# APM32F446 register map
File version: 1.0
CPU: CM4 r0p1, little endian, MPU, FPU, 4 interrupt priority bits
Registers are 32-bit, read-write, reset 0x0 unless marked. A register's access mark holds for its fields unless they carry their own. Offsets are from the block's base; [hi:lo] are bit positions; {n}, {i} and the like mark numbered series; 'fields as' and 'values as' point back to an identical list.

## CAN0 — Configurable Controller local area network
Base 0x40024000
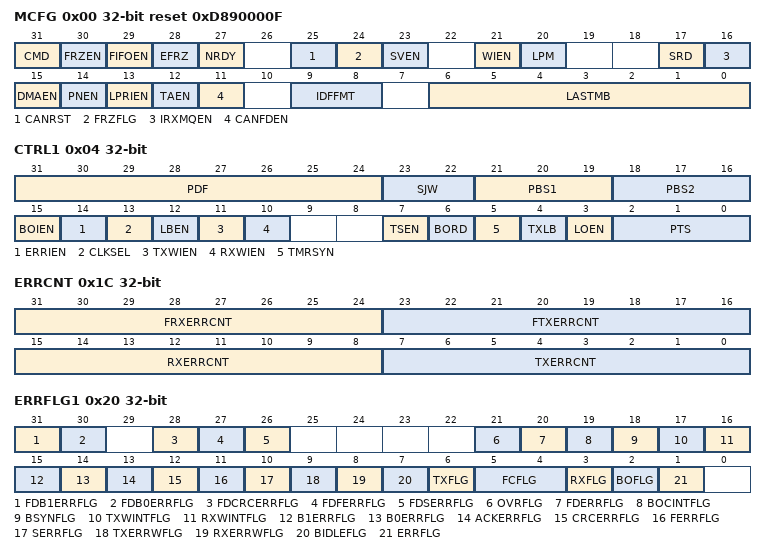
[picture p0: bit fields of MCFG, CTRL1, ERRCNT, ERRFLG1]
0x00 MCFG reset 0xD890000F — Module Configure register
  [31] CMD — CAN Module Disable
    0=Enable the CAN module; 1=Disable the CAN module
  [30] FRZEN — Freeze Mode Enable
    0=Not enabled to enter Freeze mode; 1=Enabled to enter Freeze mode
  [29] FIFOEN — Rx FIFO Enable
    0=Rx FIFO not enabled; 1=Rx FIFO enabled
  [28] EFRZ — Enter Freeze Mode
    0=No Freeze mode request; 1=Enters Freeze mode if the FRZ bit is asserted
  [27] NRDY ro — Not Ready
    0=CAN module is either in Normal mode, Listen-Only mode or Loop-Back mode
  [25] CANRST — CAN Reset
    0=No reset request; 1=Resets the registers affected by soft reset
  [24] FRZFLG ro — Freeze Mode Flag
    0=CAN not in Freeze mode, prescaler running; 1=CAN in Freeze mode, prescaler stopped
  [23] SVEN — Supervisor Mode Enable
  [21] WIEN — Warning Interrupt Enable
    0=TWRNINT and RWRNINT bits are zero, independent of the values in the error counters; 1=TWRNINT and RWRNINT bits are set when the respective error counter transitions from less than 96 to greater than or equal to 96
  [20] LPM ro — Low-Power Mode
    0=CAN is not in a low-power mode; 1=CAN is in a low-power mode
  [17] SRD — Self Reception Disable
    0=Self reception enabled; 1=Self reception disabled
  [16] IRXMQEN — Individual Receive Masking and Queue Enable
    0=Individual Rx masking and queue feature are disabled. For backward compatibility with legacy applications, the reading of C/S word locks the MB even if it is EMPTY.; 1=Individual Rx masking and queue feature are enabled
  [15] DMAEN — DMA Enable for Rx FIFO
    0=DMA feature for RX FIFO disabled; 1=DMA feature for RX FIFO enabled
  [14] PNEN — Pretended Networking Enable
    0=Pretended Networking mode is disabled; 1=Pretended Networking mode is enabled
  [13] LPRIEN — Local Priority Enable
    0=Local Priority disabled; 1=Local Priority enabled
  [12] TAEN — Tx Abort Mechanism Enable
    0=Abort disabled; 1=Abort enabled
  [11] CANFDEN — CAN FD Operation Enable
    1=CAN FD is enabled. CAN is able to receive and transmit messages in both CAN FD and CAN 2.0 formats.; 0=CAN FD is disabled. CAN is able to receive and transmit messages in CAN 2.0 format.
  [9:8] IDFFMT — Rx FIFO ID Filter Format
    0=Format A: One full ID (standard and extended) per ID Filter Table element; 1=Format B: Two full standard IDs or two partial 14-bit (standard and extended) IDs per ID Filter Table element; 2=Format C: Four partial 8-bit Standard IDs per ID Filter Table element; 3=Format D: All frames rejected
  [6:0] LASTMB — Number of the Last Message Buffer
0x04 CTRL1 — Control register 1
  [31:24] PDF — Prescaler Division Factor
  [23:22] SJW — Resynchronized Jump Width
  [21:19] PBS1 — Phase Buffer Segment 1
  [18:16] PBS2 — Phase Buffer Segment 2
  [15] BOIEN — Bus Off Interrupt Enable
    0=Bus Off interrupt disabled; 1=Bus Off interrupt enabled
  [14] ERRIEN — Error Interrupt Enable
    0=Error interrupt disabled; 1=Error interrupt enabled
  [13] CLKSEL — CAN Engine Clock Source Select
    0=The CAN engine clock source is the oscillator clock. Under this condition, the oscillator clock frequency must be lower than the bus clock.; 1=The CAN engine clock source is the peripheral clock
  [12] LBEN — Loop Back Mode Enable
    0=Loop Back disabled; 1=Loop Back enabled
  [11] TXWIEN — Tx Warning Interrupt Enable
    0=Tx Warning Interrupt disabled; 1=Tx Warning Interrupt enabled
  [10] RXWIEN — Rx Warning Interrupt Enable
    0=Rx Warning Interrupt disabled; 1=Rx Warning Interrupt enabled
  [7] TSEN — Triple Sampling Enable
    0=Just one sample is used to determine the bit value; 1=Three samples are used to determine the value of the received bit: the regular one (sample point) and 2 preceding samples; a majority rule is used
  [6] BORD — Bus Off Recovery Disable
    0=Automatic recovering from Bus Off state enabled; 1=Automatic recovering from Bus Off state disabled
  [5] TMRSYN — Timer Sync Feature Enable
    0=Timer Sync feature disabled; 1=Timer Sync feature enabled
  [4] TXLB — Transmit Lowest Buffer First
    0=Buffer with highest priority is transmitted first; 1=Lowest number buffer is transmitted first
  [3] LOEN — Listen-Only Mode Enable
    0=Listen-Only mode is deactivated; 1=CAN module operates in Listen-Only mode
  [2:0] PTS — Propagation Time Segment
0x08 FRTMR — Free Running Timer register
  [15:0] FRTMR — Free Runnning Timer Value
0x10 RXMASK reset not defined — Rx Mailboxes Global Mask register
  [31:0] RXMASK — Rx Mailboxes Global Mask
0x14 RX14MASK reset not defined
  [31:0] RX14MASK — Rx Buffer 14 Mask
0x18 RX15MASK reset not defined
  [31:0] RX15MASK — Rx Buffer 15 Mask
0x1C ERRCNT — Error Counter register
  [31:24] FRXERRCNT — Fast Receive Error Counter
  [23:16] FTXERRCNT — Fast Transmit Error Counter
  [15:8] RXERRCNT — Receive Error Counter
  [7:0] TXERRCNT — Transmit Error Counter
0x20 ERRFLG1 — Error Flag register 1
  [31] FDB1ERRFLG ro — Bit1 Error in CAN FD Frames Data Phase with BRS bit Set
    0=No such occurrence; 1=At least one bit sent as recessive is received as dominant
  [30] FDB0ERRFLG ro — Bit0 Error in CAN FD Frames Data Phase with BRS bit Set
    0=No such occurrence; 1=At least one bit sent as dominant is received as recessive
  [28] FDCRCERRFLG ro — CRC Error in CAN FD Frame Data Phasewith BRS bit Set
    0=No such occurrence; 1=A CRC error occurred since last read of this register
  [27] FDFERRFLG ro — Form Error in CAN FD Frame Data Phase with BRS bit Set
    0=No such occurrence; 1=A Form Error occurred since last read of this register
  [26] FDSERRFLG ro — Stuffing Error in CAN FD Frame Data Phase with BRS bit Set
    0=No such occurrence; 1=A Stuffing Error occurred since last read of this register
  [21] OVRFLG — Overrun Flag
    0=Overrun has not occurred; 1=Overrun has occurred
  [20] FDERRFLG — Error Interrupt Detected in CAN FD Frame Data Phase with BRS bit Set Flag
    0=No such occurrence; 1=Indicates setting of any Error Bit detected in the Data Phase of CAN FD frames with the BRS bit set
  [19] BOCINTFLG — Bus Off Process Complete Flag
    0=No such occurrence; 1=CAN module has completed Bus Off process
  [18] BSYNFLG ro — CAN Bus Synchronization Flag
    0=CAN is not synchronized to the CAN bus; 1=CAN is synchronized to the CAN bus
  [17] TXWINTFLG — Tx Warning Interrupt Flag
    0=No such occurrence; 1=The Tx error counter transitioned from less than 96 to greater than or equal to 96
  [16] RXWINTFLG — Rx Warning Interrupt Flag
    0=No such occurrence; 1=The Rx error counter transitioned from less than 96 to greater than or equal to 96
  [15] B1ERRFLG ro — Bit1 Error Flag
    values as FDB1ERRFLG
  [14] B0ERRFLG ro — Bit0 Error Flag
    values as FDB0ERRFLG
  [13] ACKERRFLG ro — Acknowledge Error Flag
    0=No such occurrence; 1=An ACK error occurred since last read of this register
  [12] CRCERRFLG ro — CRC Error Flag
    values as FDCRCERRFLG
  [11] FERRFLG ro — Form Error Flag
    values as FDFERRFLG
  [10] SERRFLG ro — Stuffing Error Flag
    values as FDSERRFLG
  [9] TXERRWFLG ro — TX Error Warning Flag
    0=No such occurrence; 1=TXERRCNT is greater than or equal to 96
  [8] RXERRWFLG ro — RX Error Warning Flag
    0=No such occurrence; 1=RXERRCNT is greater than or equal to 96
  [7] BIDLEFLG ro — Bus Idle Flag
    0=No such occurrence; 1=CAN bus is now IDLE
  [6] TXFLG ro — Being Transmit Flag
    0=CAN is not transmitting a message; 1=CAN is transmitting a message
  [5:4] FCFLG ro — Fault Confinement Flag
    0=Error Active; 1=Error Passive; 0b1x=Bus Off
  [3] RXFLG ro — Being Receive Flag
    0=CAN is not receiving a message; 1=CAN is receiving a message
  [2] BOFLG — Bus Off Flag
    0=No such occurrence; 1=CAN module entered Bus Off state
  [1] ERRFLG — Error Interrupt Flag
    0=No such occurrence; 1=Indicates setting of any Error Bit in the Error and Status Register
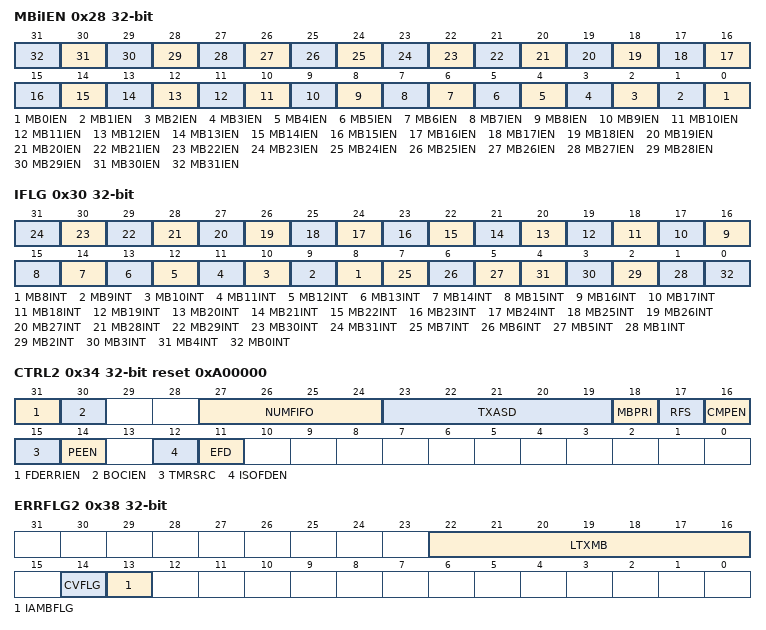
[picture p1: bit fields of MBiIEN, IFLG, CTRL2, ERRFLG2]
0x28 MBiIEN — Message Buffer i Interrupt Enable register
  [n] MB{n}IEN (n=0..31) — Buffer MB 0-31 Mask
0x30 IFLG — Interrupt Flag register
  [n] MB{n}INT (n=8..31) — MB8-31 Buffer Completed Transmission or Reception Flag
  [7] MB7INT — Buffer MB7 Interrupt or Rx FIFO Overflow Flag
    0=No occurrence of MB7 completing transmission/reception when MCFG[FIFOEN]=0, or of Rx FIFO overflow when MCFG[FIFOEN]=1; 1=MB7 completed transmission/reception when MCFG[FIFOEN]=0, or Rx FIFO overflow when MCFG[FIFOEN]=1
  [6] MB6INT — Buffer MB6 Interrupt or Rx FIFO Warning Flag
    0=No occurrence of MB6 completing transmission/reception when MCFG[FIFOEN]=0, or of Rx FIFO almost full when MCFG[FIFOEN]=1; 1=MB6 completed transmission/reception when MCFG[FIFOEN]=0, or Rx FIFO almost full when MCFG[FIFOEN]=1
  [5] MB5INT — Buffer MB5 Interrupt or Frames Available in Rx FIFO Flag
    0=No occurrence of MB5 completing transmission/reception when MCFG[FIFOEN]=0, or of frame(s) available in the FIFO, when MCFG[FIFOEN]=1; 1=MB5 completed transmission/reception when MCFG[FIFOEN]=0, or frame(s) available in the Rx FIFO when MCFG[FIFOEN]=1. It generates a DMA request in case of MCFG[FIFOEN] and MCFG[DMA] are enabled.
  [n] MB{n}INT (n=1..4) — Buffer MB{n} Interrupt or Reserved Flag
  [0] MB0INT — Buffer MB0 Interrupt or Clear FIFO Bit Flag
    0=The corresponding buffer has no occurrence of successfully completed transmission or reception when MCFG[FIFOEN]=0; 1=The corresponding buffer has successfully completed transmission or reception when MCFG[FIFOEN]=0
0x34 CTRL2 reset 0xA00000 — Control register 2
  [31] FDERRIEN — Error Interrupt Detected in Fast CAN FD Frame Data Phase Enable
    0=ERRFLG_FAST Error interrupt disabled; 1=ERRFLG_FAST Error interrupt enabled
  [30] BOCIEN — Bus Off Process Complete Interrupt Enable
    0=Bus Off Done interrupt disabled; 1=Bus Off Done interrupt enabled
  [27:24] NUMFIFO — Number of Receive FIFO Filters
  [23:19] TXASD — Transmit Arbitration Start Delay
  [18] MBPRI — Mailboxes Reception Priority Configure
    0=Matching starts from Rx FIFO and continues on Mailboxes; 1=Matching starts from Mailboxes and continues on Rx FIFO
  [17] RFS — Remote Request Frame Storing
    0=Remote Response Frame is generated; 1=Remote Request Frame is stored
  [16] CMPEN — IDE and RTR Bit Comparison Enable For Receive Mailboxes
    0=Rx Mailbox filter's IDE bit is always compared and RTR is never compared despite mask bits; 1=Enables the comparison of both Rx Mailbox filter's IDE and RTR bit with their corresponding bits within the incoming frame. Mask bits do apply.
  [15] TMRSRC — Time Source for the Free Running Timer
    0=The Free Running Timer is clocked by the CAN bit clock, which defines the baud rate on the CAN bus; 1=The Free Running Timer is clocked by an external time tick. The period can be either adjusted to be equal to the baud rate on the CAN bus, or a different value as required. See the device specific section for details about the external time tick.
  [14] PEEN — Protocol Exception Enable
    0=Protocol Exception is disabled; 1=Protocol Exception is enabled
  [12] ISOFDEN — ISO CAN FD Protocol Enable
    0=CAN operates using the non-ISO CAN FD protocol; 1=CAN operates using the ISO CAN FD protocol (ISO 11898-1)
  [11] EFD — Edge Filter Disable
    0=Edge Filter is enabled; 1=Edge Filter is disabled
0x38 ERRFLG2 ro — Error Flag register 2
  [22:16] LTXMB — Lowest Priority Transmission Mailbox Flag
  [14] CVFLG — Contents Valid Flag
    0=Contents of IMB and LPTM are invalid; 1=Contents of IMB and LPTM are valid
  [13] IAMBFLG — Inactive Mailbox Flag
    0=If ESR2[VPS] is asserted, the ESR2[LPTM] is not an inactive Mailbox; 1=If ESR2[VPS] is asserted, there is at least one inactive Mailbox. LPTM content is the number of the first one.
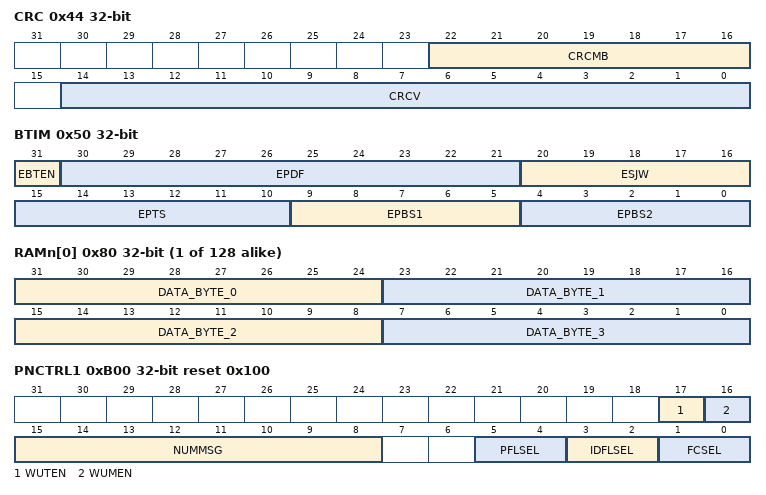
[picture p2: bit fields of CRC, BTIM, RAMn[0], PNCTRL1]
0x44 CRC ro
  [22:16] CRCMB — Number of CRC Mailbox
  [14:0] CRCV — Transmitted CRC Value
0x48 FIFOGMASK reset not defined — Rx FIFO Global Mask register
  [31:0] FIFOGMASK — Rx FIFO Global Mask
0x4C FIFOINFO ro reset not defined — Rx FIFO Information register
  [8:0] IAF — ID Acceptance Filter Hit Indicator
0x50 BTIM — Bit Timing register
  [31] EBTEN — Extended Bit Time Enable
    0=Extended bit time definitions disabled; 1=Extended bit time definitions enabled
  [30:21] EPDF — Extended Prescaler Division Factor
  [20:16] ESJW — Extended Resynchronized Jump Width
  [15:10] EPTS — Extended Propagation Time Segment
  [9:5] EPBS1 — Extended Phase Buffer Segment 1
  [4:0] EPBS2 — Extended Phase Buffer Segment 2
{0x80+4i} RAMn[{i}] (i=0..127) — Embedded RAM
  [31-8n:24-8n] DATA_BYTE_{n} (n=0..3) — Data byte {n} of Rx/Tx frame.
{0x880+4i} RXIMASK[{i}] (i=0..31) reset not defined — Rx Individual Mask registers
  [31:0] IBMASK — Individual Bits Mask
0xB00 PNCTRL1 reset 0x100 — Pretended Networking Control register 1
  [17] WUTEN — Wakeup by Timeout Event Enable
    0=Timeout wake up event is disabled; 1=Timeout wake up event is enabled
  [16] WUMEN — Wakeup by Match Event Enable
    0=Wake up match event is disabled; 1=Wake up match event is enabled
  [15:8] NUMMSG — Number of Messages Matching the Same Filtering Criteria
    1=Received message must match the predefined filtering criteria for ID and/or PL once before generating a wake up event; 2=Received message must match the predefined filtering criteria for ID and/or PL twice before generating a wake up event; 255=Received message must match the predefined filtering criteria for ID and/or PL 255 times before generating a wake up event
  [5:4] PFLSEL — Payload Filtering Level Select
    0=Match upon a payload contents against an exact target value; 1=Match upon a payload value greater than or equal to a specified target value; 2=Match upon a payload value smaller than or equal to a specified target value; 3=Match upon a payload value inside a range, greater than or equal to a specified lower limit and smaller than or equal a specified upper limit
  [3:2] IDFLSEL — ID Filtering Level Select
    0=Match upon a ID contents against an exact target value; 1=Match upon a ID value greater than or equal to a specified target value; 2=Match upon a ID value smaller than or equal to a specified target value; 3=Match upon a ID value inside a range, greater than or equal to a specified lower limit and smaller than or equal a specified upper limit
  [1:0] FCSEL — Filtering Criteria Select
    0=Message ID filtering only; 1=Message ID filtering and payload filtering; 2=Message ID filtering occurring a specified number of times; 3=Message ID filtering and payload filtering a specified number of times
0xB04 PNCTRL2 — Pretended Networking Contro register 2
  [15:0] TOV — Timeout Value for No Message Matching the Filtering Criteria
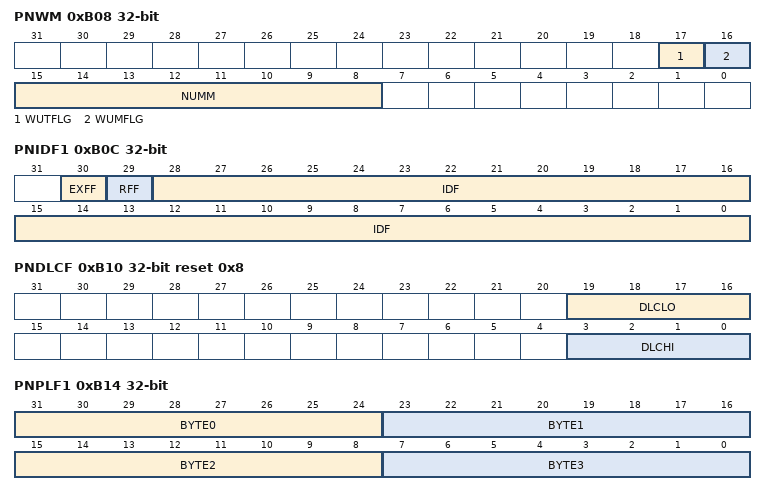
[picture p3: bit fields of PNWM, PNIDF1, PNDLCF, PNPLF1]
0xB08 PNWM — Pretended Networking Wake Up Match register
  [17] WUTFLG — Wakeup by Timeout Event Flag
    0=No wake up by timeout event detected; 1=Wake up by timeout event detected
  [16] WUMFLG — Wakeup by Match Event Flag
    0=No wake up by match event detected; 1=Wake up by match event detected
  [15:8] NUMM ro — Number of Matches when in Pretended Networking
0xB0C PNIDF1 — Pretended Networking ID Filter 1 register
  [30] EXFF — Extended Frame Format Filter
    0=Accept standard frame format; 1=Accept extended frame format
  [29] RFF — Remote Frame Filter
    0=Reject remote frame (accept data frame); 1=Accept remote frame
  [28:0] IDF — ID Filter 1 for Pretended Networking
0xB10 PNDLCF reset 0x8 — Pretended Networking Length Code Filter register
  [19:16] DLCLO — Payload Data Length Code Lower Limit
  [3:0] DLCHI — Payload Data Length Code Higher Limit
0xB14 PNPLF1 — Pretended Networking Payload Low Filter 1 register
  [31-8n:24-8n] BYTE{n} (n=0..3)
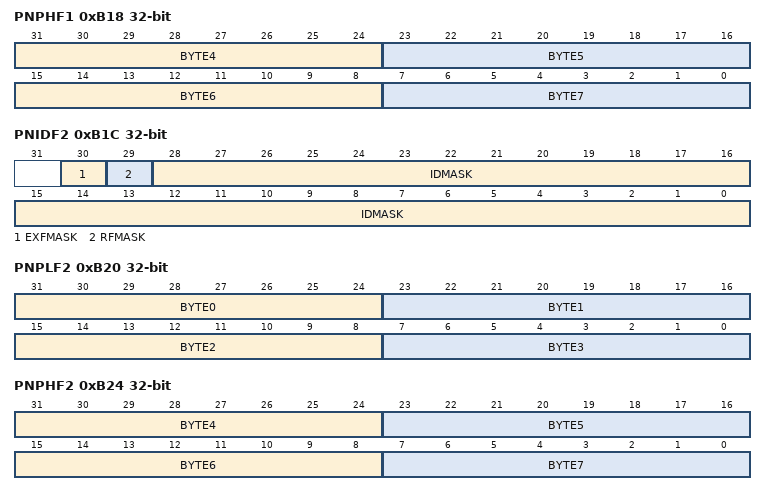
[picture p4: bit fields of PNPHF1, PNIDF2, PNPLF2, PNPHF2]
0xB18 PNPHF1 — Pretended Networking Payload High Filter 1 register
  [63-8n:56-8n] BYTE{n} (n=4..7)
0xB1C PNIDF2 — Pretended Networking ID Filter 2 Register
  [30] EXFMASK — Extended Frame Format Filter Mask
    0=The corresponding bit in the filter is "don't care"; 1=The corresponding bit in the filter is checked
  [29] RFMASK — Remote Frame Filter Mask
    values as EXFMASK
  [28:0] IDMASK — ID Mask Bits for Pretended Networking ID Filtering
0xB20 PNPLF2 — Pretended Networking Payload Low Filter 2 Register
  [31-8n:24-8n] BYTE{n} (n=0..3)
0xB24 PNPHF2 — Pretended Networking Payload High Filter 2 register
  [63-8n:56-8n] BYTE{n} (n=4..7)
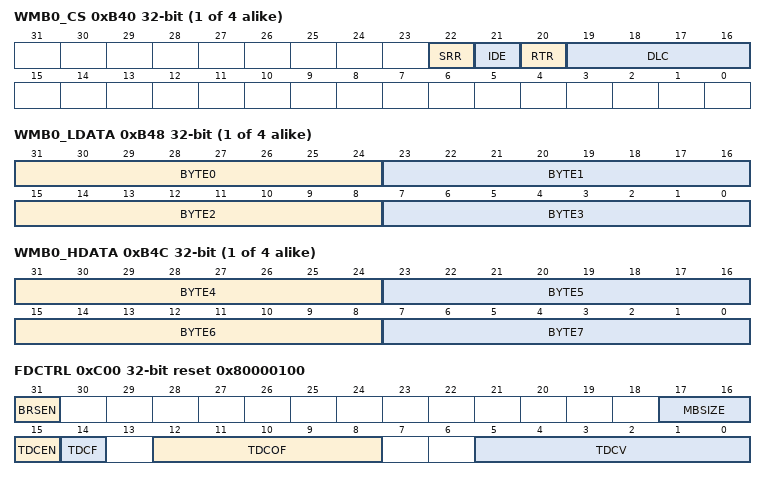
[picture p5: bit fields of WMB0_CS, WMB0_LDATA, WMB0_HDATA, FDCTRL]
{0xB40+0x10*i} WMB{i}_CS (i=0..3) ro — Wake Up Message Buffer register a for C/S
  [22] SRR — Substitute Remote Request
  [21] IDE — Identifier Extension Bit
    0=Frame format is standard; 1=Frame format is extended
  [20] RTR — Remote Transmission Request Bit
    0=Frame is data one (not remote); 1=Frame is a remote one
  [19:16] DLC — Data Length Code
{0xB44+0x10*i} WMB{i}_ID (i=0..3) ro — Wake Up Message Buffer Register a for ID
  [28:0] WMID — Wake Up Message ID
{0xB48+0x10*i} WMB{i}_LDATA (i=0..3) ro — Wake Up Message Buffer Register a Low Data
  [31-8n:24-8n] BYTE{n} (n=0..3)
{0xB4C+0x10*i} WMB{i}_HDATA (i=0..3) ro — Wake Up Message Buffer Register a for High Data
  [63-8n:56-8n] BYTE{n} (n=4..7)
0xC00 FDCTRL reset 0x80000100 — FD Control register
  [31] BRSEN — Bit Rate Switch Enable
    0=Transmit a frame in nominal rate. The BRS bit in the Tx MB has no effect.; 1=Transmit a frame with bit rate switching if the BRS bit in the Tx MB is recessive
  [17:16] MBSIZE — Message Buffer Data Size for Region 0
    0=Selects 8 bytes per Message Buffer; 1=Selects 16 bytes per Message Buffer; 2=Selects 32 bytes per Message Buffer; 3=Selects 64 bytes per Message Buffer
  [15] TDCEN — Transceiver Delay Compensation Feature Enable
    0=TDC is disabled; 1=TDC is enabled
  [14] TDCF — Transceiver Delay Compensation Mechanism has Failed
    0=Measured loop delay is in range; 1=Measured loop delay is out of range
  [12:8] TDCOF — Transceiver Delay Compensation Offset
  [5:0] TDCV ro — Transceiver Delay Compensation Value
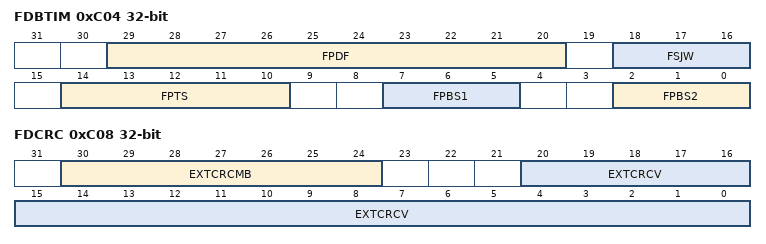
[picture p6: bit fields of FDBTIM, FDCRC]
0xC04 FDBTIM — FD Bit Timing register
  [29:20] FPDF — Fast Prescaler Division Factor
  [18:16] FSJW — Fast Resynchronized Jump Width
  [14:10] FPTS — Fast Propagation Time Segment
  [7:5] FPBS1 — Fast Phase Buffer Segment 1
  [2:0] FPBS2 — Fast Phase Buffer Segment 2
0xC08 FDCRC ro
  [30:24] EXTCRCMB — Number of Extended CRC Mailbox
  [20:0] EXTCRCV — Extended CRC Value of the Transmitted Message

## CAN1 — Configurable Controller local area network
Base 0x40025000
Registers as CAN0, without PNDLCF, FDBTIM; these are added or differ:
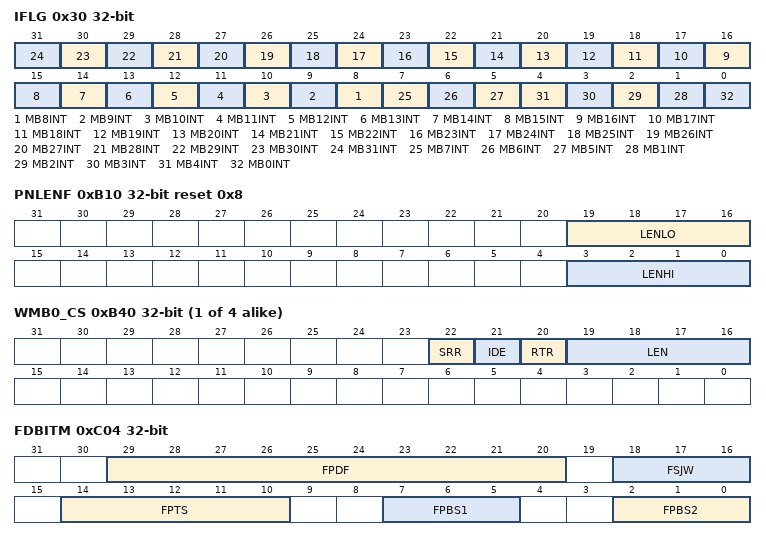
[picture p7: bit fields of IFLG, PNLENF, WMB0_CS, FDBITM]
0x30 IFLG — Interrupt Flag register
  [n] MB{n}INT (n=8..31) — MB8-31 Buffer Completed Transmission or Reception Flag
  [7] MB7INT — Buffer MB7 Interrupt or Rx FIFO Overflow Flag
    values as CAN0.IFLG.MB7INT
  [6] MB6INT — Buffer MB6 Interrupt or Rx FIFO Warning Flag
    values as CAN0.IFLG.MB6INT
  [5] MB5INT — Buffer MB5 Interrupt or Frames Available in Rx FIFO Flag
    0=No occurrence of MB5 completing transmission/reception when MCFG[FIFOEN]=0, or of frame(s) available in the FIFO, when MCFG[FIFOEN]=1; 1=MB5 completed transmission/reception when MCFG[FIFOEN]=0, or frame(s) available in the Rx FIFO when MCFG[FIFOEN]=1. It generates a DMA request in case of MCFG[FIFOEN] and MCR[DMA] are enabled.
  [n] MB{n}INT (n=1..4) — Buffer MB{n} Interrupt or Reserved Flag
  [0] MB0INT — Buffer MB0 Interrupt or Clear FIFO Bit Flag
    values as CAN0.IFLG.MB0INT
0xB10 PNLENF reset 0x8 — Pretended Networking Length Filter register
  [19:16] LENLO — Payload Length Lower Limit
  [3:0] LENHI — Payload Length Upper Limit
{0xB40+0x10*i} WMB{i}_CS (i=0..3) ro — Wake Up Message Buffer register a for C/S
  [22] SRR — Substitute Remote Request
  [21] IDE — Identifier Extension Bit
    0=Frame format is standard; 1=Frame format is extended
  [20] RTR — Remote Transmission Request Bit
    0=Frame is data one (not remote); 1=Frame is a remote one
  [19:16] LEN — Length of Received Data
0xC04 FDBITM — FD Bit Timing register
  fields as CAN0.FDBTIM

## CAN2 — Configurable Controller local area network
Base 0x4002B000
Registers as CAN1, without RAMn[*], RXIMASK[*]; these are added or differ:
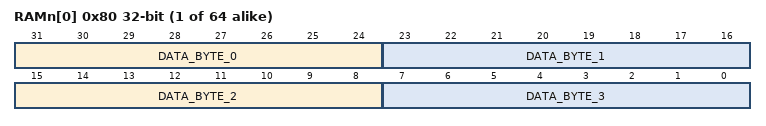
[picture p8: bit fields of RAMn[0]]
{0x80+4i} RAMn[{i}] (i=0..63) — Embedded RAM
  [31-8n:24-8n] DATA_BYTE_{n} (n=0..3) — Data byte {n} of Rx/Tx frame.
{0x880+4i} RXIMASK[{i}] (i=0..15) reset not defined — Rx Individual Mask registers
  [31:0] IBMASK — Individual Bits Mask
